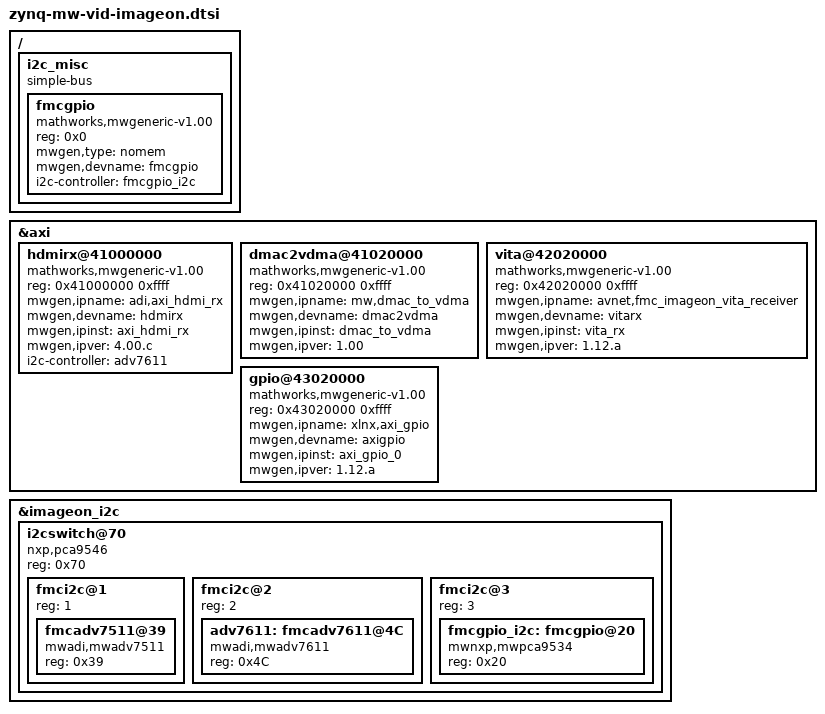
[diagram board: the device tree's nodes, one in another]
/{
    i2c_misc {
        compatible = "simple-bus";
		#address-cells = <0x1>;
		#size-cells = <0x0>;

        fmcgpio {
            compatible = "mathworks,mwgeneric-v1.00";       
            reg = <0x0>;    
            mwgen,type = "nomem";            
            mwgen,devname = "fmcgpio";            
            i2c-controller = <&fmcgpio_i2c>;
        };
    };
};
&axi{   
	hdmirx@41000000 {
		compatible = "mathworks,mwgeneric-v1.00";
		reg = <0x41000000 0xffff>;
		mwgen,ipname = "adi,axi_hdmi_rx";
		mwgen,devname = "hdmirx";
		mwgen,ipinst = "axi_hdmi_rx";
		mwgen,ipver = "4.00.c";
        i2c-controller = <&adv7611>;
	};

    dmac2vdma@41020000 {
		compatible = "mathworks,mwgeneric-v1.00";
		reg = <0x41020000 0xffff>;
		mwgen,ipname = "mw,dmac_to_vdma";
		mwgen,devname = "dmac2vdma";
		mwgen,ipinst = "dmac_to_vdma";
		mwgen,ipver = "1.00";
	};
	
	vita@42020000 {
		compatible = "mathworks,mwgeneric-v1.00";
		reg = <0x42020000 0xffff>;
		mwgen,ipname = "avnet,fmc_imageon_vita_receiver";
		mwgen,devname = "vitarx";
		mwgen,ipinst = "vita_rx";
		mwgen,ipver = "1.12.a";
	};
	
	gpio@43020000 {
		compatible = "mathworks,mwgeneric-v1.00";
		reg = <0x43020000 0xffff>;
		mwgen,ipname = "xlnx,axi_gpio";
		mwgen,devname = "axigpio";
		mwgen,ipinst = "axi_gpio_0";
		mwgen,ipver = "1.12.a";
	};
};

&imageon_i2c {
	i2cswitch@70 {
			compatible = "nxp,pca9546";
			#address-cells = <1>;
			#size-cells = <0>;
			reg = <0x70>;            
		
			fmci2c@1 {
				#address-cells = <1>;
				#size-cells = <0>;
				reg = <1>;
				
				fmcadv7511@39 {
					compatible = "mwadi,mwadv7511";
					reg = <0x39>;
				};
				
			};
			fmci2c@2 {
				#address-cells = <1>;
				#size-cells = <0>;
				reg = <2>;

				adv7611: fmcadv7611@4C {
					compatible = "mwadi,mwadv7611";
					reg = <0x4C>;
				};

			};
			fmci2c@3 {
				#address-cells = <1>;
				#size-cells = <0>;
				reg = <3>;
				
				fmcgpio_i2c: fmcgpio@20 {
					compatible = "mwnxp,mwpca9534";
					reg = <0x20>;
				};
			};
		};
};
